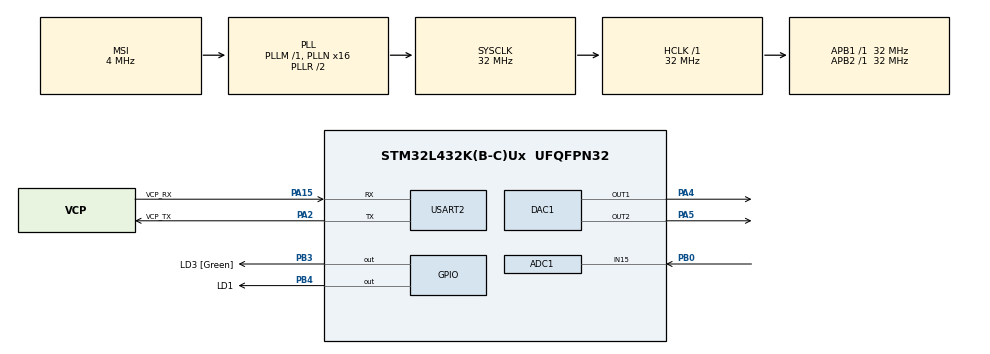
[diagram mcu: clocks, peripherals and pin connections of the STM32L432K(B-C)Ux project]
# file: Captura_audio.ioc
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ADC1.Channel-3\#ChannelRegularConversion=ADC_CHANNEL_15
ADC1.ClockPrescaler=ADC_CLOCK_SYNC_PCLK_DIV1
ADC1.ExternalTrigConv=ADC_EXTERNALTRIG_T6_TRGO
ADC1.NbrOfConversionFlag=1
ADC1.OffsetNumber-3\#ChannelRegularConversion=ADC_OFFSET_NONE
ADC1.Rank-3\#ChannelRegularConversion=1
ADC1.SamplingTime-3\#ChannelRegularConversion=ADC_SAMPLETIME_24CYCLES_5
ADC1.master=1
DAC1.DAC_Channel-DAC_OUT2=DAC_CHANNEL_2
DAC1.DAC_Trigger-DAC_OUT1=DAC_TRIGGER_T2_TRGO
DAC1.DAC_Trigger-DAC_OUT2=DAC_TRIGGER_T6_TRGO
DAC1.TriangleAmplitude-DAC_OUT1=DAC_TRIANGLEAMPLITUDE_4095
DAC1.WaveGeneration-DAC_OUT1=TriangleWaveGeneration
Dma.ADC1.1.Direction=DMA_PERIPH_TO_MEMORY
Dma.ADC1.1.Instance=DMA2_Channel3
Dma.ADC1.1.MemDataAlignment=DMA_MDATAALIGN_HALFWORD
Dma.ADC1.1.MemInc=DMA_MINC_ENABLE
Dma.ADC1.1.Mode=DMA_CIRCULAR
Dma.ADC1.1.PeriphDataAlignment=DMA_PDATAALIGN_HALFWORD
Dma.ADC1.1.PeriphInc=DMA_PINC_DISABLE
Dma.ADC1.1.Priority=DMA_PRIORITY_LOW
Dma.DAC_CH2.2.Direction=DMA_MEMORY_TO_PERIPH
Dma.DAC_CH2.2.Instance=DMA1_Channel4
Dma.DAC_CH2.2.MemDataAlignment=DMA_MDATAALIGN_HALFWORD
Dma.DAC_CH2.2.MemInc=DMA_MINC_ENABLE
Dma.DAC_CH2.2.Mode=DMA_NORMAL
Dma.DAC_CH2.2.PeriphDataAlignment=DMA_PDATAALIGN_HALFWORD
Dma.DAC_CH2.2.PeriphInc=DMA_PINC_DISABLE
Dma.DAC_CH2.2.Priority=DMA_PRIORITY_LOW
Dma.Request0=USART2_TX
Dma.Request1=ADC1
Dma.Request2=DAC_CH2
Dma.USART2_TX.0.Direction=DMA_MEMORY_TO_PERIPH
Dma.USART2_TX.0.Instance=DMA1_Channel7
Dma.USART2_TX.0.MemDataAlignment=DMA_MDATAALIGN_BYTE
Dma.USART2_TX.0.MemInc=DMA_MINC_ENABLE
Dma.USART2_TX.0.Mode=DMA_NORMAL
Dma.USART2_TX.0.PeriphDataAlignment=DMA_PDATAALIGN_BYTE
Dma.USART2_TX.0.PeriphInc=DMA_PINC_DISABLE
Dma.USART2_TX.0.Priority=DMA_PRIORITY_LOW
Mcu.Family=STM32L4
Mcu.Name=STM32L432K(B-C)Ux
Mcu.Package=UFQFPN32
NVIC.DMA1_Channel4_IRQn=true\:0\:0\:false\:false\:true\:false\:true
NVIC.DMA1_Channel7_IRQn=true\:0\:0\:false\:false\:true\:false\:true
NVIC.DMA2_Channel3_IRQn=true\:0\:0\:false\:false\:true\:false\:true
NVIC.PriorityGroup=NVIC_PRIORITYGROUP_4
NVIC.USART2_IRQn=true\:0\:0\:false\:false\:true\:true\:true
PA0.GPIO_Label=MCO [High speed clock in]
PA0.Mode=HSE-External-Clock-Source-for-LittleOrca
PA0.Signal=RCC_CK_IN
PA13\ (JTMS-SWDIO).GPIO_Label=SWDIO
PA13\ (JTMS-SWDIO).Mode=Serial_Wire
PA13\ (JTMS-SWDIO).Signal=SYS_JTMS-SWDIO
PA14\ (JTCK-SWCLK).GPIO_Label=SWCLK
PA14\ (JTCK-SWCLK).Mode=Serial_Wire
PA14\ (JTCK-SWCLK).Signal=SYS_JTCK-SWCLK
PA15\ (JTDI).GPIO_Label=VCP_RX
PA15\ (JTDI).Mode=Asynchronous
PA15\ (JTDI).Signal=USART2_RX
PA2.GPIO_Label=VCP_TX
PA2.Mode=Asynchronous
PA2.Signal=USART2_TX
PA4.Signal=COMP_DAC11_group
PA5.Signal=COMP_DAC12_group
PB0.Signal=ADCx_IN15
PB3\ (JTDO-TRACESWO).GPIO_Label=LD3 [Green]
PB3\ (JTDO-TRACESWO).GPIO_ModeDefaultOutputPP=GPIO_MODE_OUTPUT_PP
PB3\ (JTDO-TRACESWO).Signal=GPIO_Output
PB4\ (NJTRST).GPIO_Label=LD1
PB4\ (NJTRST).Signal=GPIO_Output
PC14-OSC32_IN\ (PC14).Mode=LSE-External-Oscillator
PC14-OSC32_IN\ (PC14).Signal=RCC_OSC32_IN
PC15-OSC32_OUT\ (PC15).Mode=LSE-External-Oscillator
PC15-OSC32_OUT\ (PC15).Signal=RCC_OSC32_OUT
ProjectManager.HeapSize=0x200
ProjectManager.StackSize=0x400
ProjectManager.TargetToolchain=STM32CubeIDE
RCC.ADCCLockSelection=RCC_ADCCLKSOURCE_SYSCLK
RCC.ADCFreq_Value=32000000
RCC.AHBFreq_Value=32000000
RCC.APB1Freq_Value=32000000
RCC.APB1TimFreq_Value=32000000
RCC.APB2Freq_Value=32000000
RCC.APB2TimFreq_Value=32000000
RCC.CortexFreq_Value=32000000
RCC.HCLKFreq_Value=32000000
RCC.HSE_VALUE=8000000
RCC.HSI16_VALUE=16000000
RCC.HSI48_VALUE=48000000
RCC.HSI_VALUE=16000000
RCC.MSI_VALUE=4000000
RCC.PLLMUL=RCC_PLLMUL_4
RCC.PLLN=16
RCC.SYSCLKFreq_VALUE=32000000
RCC.SYSCLKSource=RCC_SYSCLKSOURCE_PLLCLK
RCC.VCOOutputFreq_Value=64000000
SH.ADCx_IN15.0=ADC1_IN15,IN15-Single-Ended
SH.COMP_DAC11_group.0=DAC1_OUT1,DAC_OUT1
SH.COMP_DAC12_group.0=DAC1_OUT2,DAC_OUT2
TIM2.Period=4
TIM2.TIM_MasterOutputTrigger=TIM_TRGO_UPDATE
TIM6.Period=4000
TIM6.TIM_MasterOutputTrigger=TIM_TRGO_UPDATE
USART2.VirtualMode-Asynchronous=VM_ASYNC
VP_TIM2_VS_ClockSourceINT.Mode=Internal
VP_TIM6_VS_ClockSourceINT.Mode=Enable_Timer
board=NUCLEO-L432KC

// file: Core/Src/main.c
/* USER CODE BEGIN Header */
/**
  ******************************************************************************
  * @file           : main.c
  * @brief          : Main program body
  ******************************************************************************
  * @attention
  *
  * <h2><center>&copy; Copyright (c) 2021 STMicroelectronics.
  * All rights reserved.</center></h2>
  *
  * This software component is licensed by ST under BSD 3-Clause license,
  * the "License"; You may not use this file except in compliance with the
  * License. You may obtain a copy of the License at:
  *                        opensource.org/licenses/BSD-3-Clause
  *
  ******************************************************************************
  */
/* USER CODE END Header */
#include "main.h"

ADC_HandleTypeDef hadc1;
DMA_HandleTypeDef hdma_adc1;

DAC_HandleTypeDef hdac1;
DMA_HandleTypeDef hdma_dac_ch2;

TIM_HandleTypeDef htim2;
TIM_HandleTypeDef htim6;

UART_HandleTypeDef huart2;
DMA_HandleTypeDef hdma_usart2_tx;

/* USER CODE BEGIN PV */
uint16_t amostras[4096];
/* USER CODE END PV */

void SystemClock_Config(void);
static void MX_GPIO_Init(void);
static void MX_DMA_Init(void);
static void MX_USART2_UART_Init(void);
static void MX_ADC1_Init(void);
static void MX_DAC1_Init(void);
static void MX_TIM2_Init(void);
static void MX_TIM6_Init(void);

/* USER CODE BEGIN 0 */
void HAL_ADC_ConvCpltCallback(ADC_HandleTypeDef *hadc)
{
	if( hadc->Instance == hadc1.Instance )
	{
		HAL_DAC_Start_DMA(&hdac1, DAC_CHANNEL_2, (uint32_t*)&amostras[2048], 2048, DAC_ALIGN_12B_R);
	}
}

void HAL_ADC_ConvHalfCpltCallback(ADC_HandleTypeDef *hadc)
{
	if( hadc->Instance == hadc1.Instance )
	{
		HAL_DAC_Start_DMA(&hdac1, DAC_CHANNEL_2, (uint32_t*)&amostras[0], 2048, DAC_ALIGN_12B_R);
	}
}
/* USER CODE END 0 */

int main(void)
{

  /* MCU Configuration--------------------------------------------------------*/

  /* Reset of all peripherals, Initializes the Flash interface and the Systick. */
  HAL_Init();

  /* Configure the system clock */
  SystemClock_Config();

  /* Initialize all configured peripherals */
  MX_GPIO_Init();
  MX_DMA_Init();
  MX_USART2_UART_Init();
  MX_ADC1_Init();
  MX_DAC1_Init();
  MX_TIM2_Init();
  MX_TIM6_Init();
  /* USER CODE BEGIN 2 */
  HAL_TIM_Base_Start(&htim2);

  HAL_DAC_Start(&hdac1, DAC_CHANNEL_1);

  HAL_TIM_Base_Start(&htim6);

  HAL_ADCEx_Calibration_Start(&hadc1, ADC_SINGLE_ENDED);

  HAL_ADC_Start_DMA(&hadc1, (uint32_t*)amostras, 4096);
  /* USER CODE END 2 */

  /* Infinite loop */
  /* USER CODE BEGIN WHILE */
  while (1)
  {
	  __WFI();
    /* USER CODE END WHILE */

  }
}

void SystemClock_Config(void)
{
  RCC_OscInitTypeDef RCC_OscInitStruct = {0};
  RCC_ClkInitTypeDef RCC_ClkInitStruct = {0};

  /** Configure the main internal regulator output voltage
  */
  if (HAL_PWREx_ControlVoltageScaling(PWR_REGULATOR_VOLTAGE_SCALE1) != HAL_OK)
  {
    Error_Handler();
  }
  /** Configure LSE Drive Capability
  */
  HAL_PWR_EnableBkUpAccess();
  __HAL_RCC_LSEDRIVE_CONFIG(RCC_LSEDRIVE_LOW);
  /** Initializes the RCC Oscillators according to the specified parameters
  * in the RCC_OscInitTypeDef structure.
  */
  RCC_OscInitStruct.OscillatorType = RCC_OSCILLATORTYPE_LSE|RCC_OSCILLATORTYPE_MSI;
  RCC_OscInitStruct.LSEState = RCC_LSE_ON;
  RCC_OscInitStruct.MSIState = RCC_MSI_ON;
  RCC_OscInitStruct.MSICalibrationValue = 0;
  RCC_OscInitStruct.MSIClockRange = RCC_MSIRANGE_6;
  RCC_OscInitStruct.PLL.PLLState = RCC_PLL_ON;
  RCC_OscInitStruct.PLL.PLLSource = RCC_PLLSOURCE_MSI;
  RCC_OscInitStruct.PLL.PLLM = 1;
  RCC_OscInitStruct.PLL.PLLN = 16;
  RCC_OscInitStruct.PLL.PLLP = RCC_PLLP_DIV7;
  RCC_OscInitStruct.PLL.PLLQ = RCC_PLLQ_DIV2;
  RCC_OscInitStruct.PLL.PLLR = RCC_PLLR_DIV2;
  if (HAL_RCC_OscConfig(&RCC_OscInitStruct) != HAL_OK)
  {
    Error_Handler();
  }
  /** Initializes the CPU, AHB and APB buses clocks
  */
  RCC_ClkInitStruct.ClockType = RCC_CLOCKTYPE_HCLK|RCC_CLOCKTYPE_SYSCLK
                              |RCC_CLOCKTYPE_PCLK1|RCC_CLOCKTYPE_PCLK2;
  RCC_ClkInitStruct.SYSCLKSource = RCC_SYSCLKSOURCE_PLLCLK;
  RCC_ClkInitStruct.AHBCLKDivider = RCC_SYSCLK_DIV1;
  RCC_ClkInitStruct.APB1CLKDivider = RCC_HCLK_DIV1;
  RCC_ClkInitStruct.APB2CLKDivider = RCC_HCLK_DIV1;

  if (HAL_RCC_ClockConfig(&RCC_ClkInitStruct, FLASH_LATENCY_1) != HAL_OK)
  {
    Error_Handler();
  }
  /** Enable MSI Auto calibration
  */
  HAL_RCCEx_EnableMSIPLLMode();
}

static void MX_ADC1_Init(void)
{

  ADC_ChannelConfTypeDef sConfig = {0};

  /** Common config
  */
  hadc1.Instance = ADC1;
  hadc1.Init.ClockPrescaler = ADC_CLOCK_SYNC_PCLK_DIV1;
  hadc1.Init.Resolution = ADC_RESOLUTION_12B;
  hadc1.Init.DataAlign = ADC_DATAALIGN_RIGHT;
  hadc1.Init.ScanConvMode = ADC_SCAN_DISABLE;
  hadc1.Init.EOCSelection = ADC_EOC_SINGLE_CONV;
  hadc1.Init.LowPowerAutoWait = DISABLE;
  hadc1.Init.ContinuousConvMode = DISABLE;
  hadc1.Init.NbrOfConversion = 1;
  hadc1.Init.DiscontinuousConvMode = DISABLE;
  hadc1.Init.ExternalTrigConv = ADC_EXTERNALTRIG_T6_TRGO;
  hadc1.Init.ExternalTrigConvEdge = ADC_EXTERNALTRIGCONVEDGE_RISING;
  hadc1.Init.DMAContinuousRequests = DISABLE;
  hadc1.Init.Overrun = ADC_OVR_DATA_PRESERVED;
  hadc1.Init.OversamplingMode = DISABLE;
  if (HAL_ADC_Init(&hadc1) != HAL_OK)
  {
    Error_Handler();
  }
  /** Configure Regular Channel
  */
  sConfig.Channel = ADC_CHANNEL_15;
  sConfig.Rank = ADC_REGULAR_RANK_1;
  sConfig.SamplingTime = ADC_SAMPLETIME_24CYCLES_5;
  sConfig.SingleDiff = ADC_SINGLE_ENDED;
  sConfig.OffsetNumber = ADC_OFFSET_NONE;
  sConfig.Offset = 0;
  if (HAL_ADC_ConfigChannel(&hadc1, &sConfig) != HAL_OK)
  {
    Error_Handler();
  }

}

static void MX_DAC1_Init(void)
{

  DAC_ChannelConfTypeDef sConfig = {0};

  /** DAC Initialization
  */
  hdac1.Instance = DAC1;
  if (HAL_DAC_Init(&hdac1) != HAL_OK)
  {
    Error_Handler();
  }
  /** DAC channel OUT1 config
  */
  sConfig.DAC_SampleAndHold = DAC_SAMPLEANDHOLD_DISABLE;
  sConfig.DAC_Trigger = DAC_TRIGGER_T2_TRGO;
  sConfig.DAC_OutputBuffer = DAC_OUTPUTBUFFER_ENABLE;
  sConfig.DAC_ConnectOnChipPeripheral = DAC_CHIPCONNECT_DISABLE;
  sConfig.DAC_UserTrimming = DAC_TRIMMING_FACTORY;
  if (HAL_DAC_ConfigChannel(&hdac1, &sConfig, DAC_CHANNEL_1) != HAL_OK)
  {
    Error_Handler();
  }
  /** Configure Triangle wave generation on DAC OUT1
  */
  if (HAL_DACEx_TriangleWaveGenerate(&hdac1, DAC_CHANNEL_1, DAC_TRIANGLEAMPLITUDE_4095) != HAL_OK)
  {
    Error_Handler();
  }
  /** DAC channel OUT2 config
  */
  sConfig.DAC_Trigger = DAC_TRIGGER_T6_TRGO;
  if (HAL_DAC_ConfigChannel(&hdac1, &sConfig, DAC_CHANNEL_2) != HAL_OK)
  {
    Error_Handler();
  }

}

static void MX_TIM2_Init(void)
{

  TIM_ClockConfigTypeDef sClockSourceConfig = {0};
  TIM_MasterConfigTypeDef sMasterConfig = {0};

  htim2.Instance = TIM2;
  htim2.Init.Prescaler = 0;
  htim2.Init.CounterMode = TIM_COUNTERMODE_UP;
  htim2.Init.Period = 4;
  htim2.Init.ClockDivision = TIM_CLOCKDIVISION_DIV1;
  htim2.Init.AutoReloadPreload = TIM_AUTORELOAD_PRELOAD_DISABLE;
  if (HAL_TIM_Base_Init(&htim2) != HAL_OK)
  {
    Error_Handler();
  }
  sClockSourceConfig.ClockSource = TIM_CLOCKSOURCE_INTERNAL;
  if (HAL_TIM_ConfigClockSource(&htim2, &sClockSourceConfig) != HAL_OK)
  {
    Error_Handler();
  }
  sMasterConfig.MasterOutputTrigger = TIM_TRGO_UPDATE;
  sMasterConfig.MasterSlaveMode = TIM_MASTERSLAVEMODE_DISABLE;
  if (HAL_TIMEx_MasterConfigSynchronization(&htim2, &sMasterConfig) != HAL_OK)
  {
    Error_Handler();
  }

}

static void MX_TIM6_Init(void)
{

  TIM_MasterConfigTypeDef sMasterConfig = {0};

  htim6.Instance = TIM6;
  htim6.Init.Prescaler = 0;
  htim6.Init.CounterMode = TIM_COUNTERMODE_UP;
  htim6.Init.Period = 4000;
  htim6.Init.AutoReloadPreload = TIM_AUTORELOAD_PRELOAD_DISABLE;
  if (HAL_TIM_Base_Init(&htim6) != HAL_OK)
  {
    Error_Handler();
  }
  sMasterConfig.MasterOutputTrigger = TIM_TRGO_UPDATE;
  sMasterConfig.MasterSlaveMode = TIM_MASTERSLAVEMODE_DISABLE;
  if (HAL_TIMEx_MasterConfigSynchronization(&htim6, &sMasterConfig) != HAL_OK)
  {
    Error_Handler();
  }

}

static void MX_USART2_UART_Init(void)
{

  huart2.Instance = USART2;
  huart2.Init.BaudRate = 115200;
  huart2.Init.WordLength = UART_WORDLENGTH_8B;
  huart2.Init.StopBits = UART_STOPBITS_1;
  huart2.Init.Parity = UART_PARITY_NONE;
  huart2.Init.Mode = UART_MODE_TX_RX;
  huart2.Init.HwFlowCtl = UART_HWCONTROL_NONE;
  huart2.Init.OverSampling = UART_OVERSAMPLING_16;
  huart2.Init.OneBitSampling = UART_ONE_BIT_SAMPLE_DISABLE;
  huart2.AdvancedInit.AdvFeatureInit = UART_ADVFEATURE_NO_INIT;
  if (HAL_UART_Init(&huart2) != HAL_OK)
  {
    Error_Handler();
  }

}

static void MX_DMA_Init(void)
{

  /* DMA controller clock enable */
  __HAL_RCC_DMA1_CLK_ENABLE();
  __HAL_RCC_DMA2_CLK_ENABLE();

  /* DMA interrupt init */
  /* DMA1_Channel4_IRQn interrupt configuration */
  HAL_NVIC_SetPriority(DMA1_Channel4_IRQn, 0, 0);
  HAL_NVIC_EnableIRQ(DMA1_Channel4_IRQn);
  /* DMA1_Channel7_IRQn interrupt configuration */
  HAL_NVIC_SetPriority(DMA1_Channel7_IRQn, 0, 0);
  HAL_NVIC_EnableIRQ(DMA1_Channel7_IRQn);
  /* DMA2_Channel3_IRQn interrupt configuration */
  HAL_NVIC_SetPriority(DMA2_Channel3_IRQn, 0, 0);
  HAL_NVIC_EnableIRQ(DMA2_Channel3_IRQn);

}

static void MX_GPIO_Init(void)
{
  GPIO_InitTypeDef GPIO_InitStruct = {0};

  /* GPIO Ports Clock Enable */
  __HAL_RCC_GPIOC_CLK_ENABLE();
  __HAL_RCC_GPIOA_CLK_ENABLE();
  __HAL_RCC_GPIOB_CLK_ENABLE();
  __HAL_RCC_GPIOH_CLK_ENABLE();

  /*Configure GPIO pin Output Level */
  HAL_GPIO_WritePin(GPIOB, LD3_Pin|LD1_Pin, GPIO_PIN_RESET);

  /*Configure GPIO pins : PA1 PA3 PA6 PA7
                           PA8 PA9 PA10 PA11
                           PA12 */
  GPIO_InitStruct.Pin = GPIO_PIN_1|GPIO_PIN_3|GPIO_PIN_6|GPIO_PIN_7
                          |GPIO_PIN_8|GPIO_PIN_9|GPIO_PIN_10|GPIO_PIN_11
                          |GPIO_PIN_12;
  GPIO_InitStruct.Mode = GPIO_MODE_ANALOG;
  GPIO_InitStruct.Pull = GPIO_NOPULL;
  HAL_GPIO_Init(GPIOA, &GPIO_InitStruct);

  /*Configure GPIO pins : PB1 PB5 PB6 PB7 */
  GPIO_InitStruct.Pin = GPIO_PIN_1|GPIO_PIN_5|GPIO_PIN_6|GPIO_PIN_7;
  GPIO_InitStruct.Mode = GPIO_MODE_ANALOG;
  GPIO_InitStruct.Pull = GPIO_NOPULL;
  HAL_GPIO_Init(GPIOB, &GPIO_InitStruct);

  /*Configure GPIO pins : LD3_Pin LD1_Pin */
  GPIO_InitStruct.Pin = LD3_Pin|LD1_Pin;
  GPIO_InitStruct.Mode = GPIO_MODE_OUTPUT_PP;
  GPIO_InitStruct.Pull = GPIO_NOPULL;
  GPIO_InitStruct.Speed = GPIO_SPEED_FREQ_LOW;
  HAL_GPIO_Init(GPIOB, &GPIO_InitStruct);

  /*Configure GPIO pin : PH3 */
  GPIO_InitStruct.Pin = GPIO_PIN_3;
  GPIO_InitStruct.Mode = GPIO_MODE_ANALOG;
  GPIO_InitStruct.Pull = GPIO_NOPULL;
  HAL_GPIO_Init(GPIOH, &GPIO_InitStruct);

}

void Error_Handler(void)
{
  __disable_irq();
  while (1)
  {
  }
}

/************************ (C) COPYRIGHT STMicroelectronics *****END OF FILE****/
